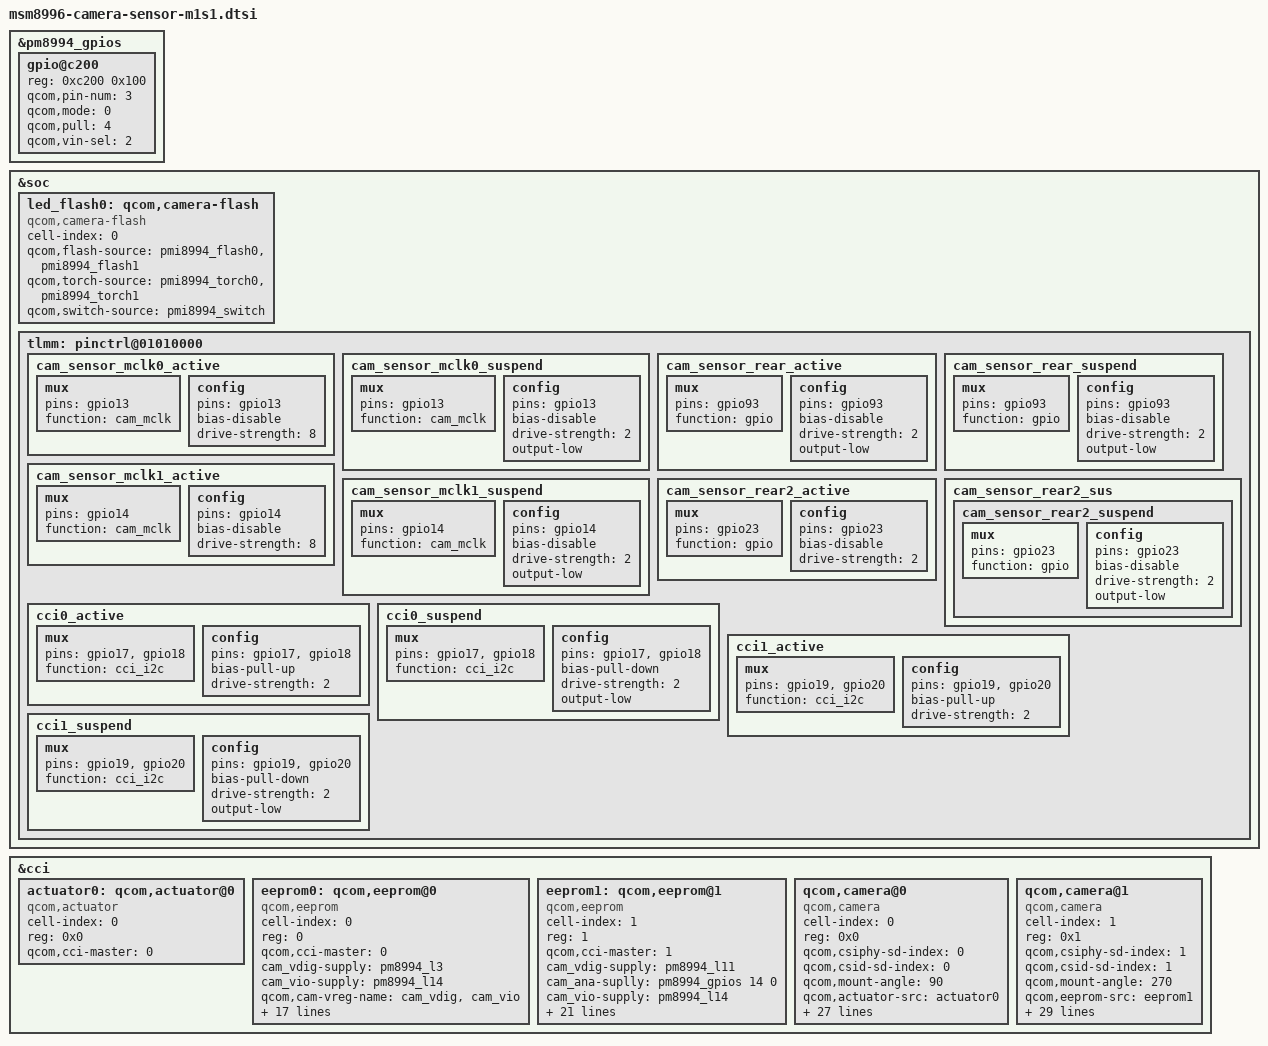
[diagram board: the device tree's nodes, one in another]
/*
 * Copyright (c) 2015, The Linux Foundation. All rights reserved.
 *
 * This program is free software; you can redistribute it and/or modify
 * it under the terms of the GNU General Public License version 2 and
 * only version 2 as published by the Free Software Foundation.
 *
 * This program is distributed in the hope that it will be useful,
 * but WITHOUT ANY WARRANTY; without even the implied warranty of
 * MERCHANTABILITY or FITNESS FOR A PARTICULAR PURPOSE.  See the
 * GNU General Public License for more details.
 */

&pm8994_gpios {
	gpio@c200 { /* Rear Camera VSYNC */
				reg = <0xc200 0x100>;
				qcom,pin-num = <3>;
				qcom,mode = <0>;     /* Digital Input */
				qcom,pull = <4>;     /* Pull Down*/
				qcom,vin-sel = <2>;  /* VIN2 */
				status = "ok";
			};
};

&soc {
	led_flash0: qcom,camera-flash {
		cell-index = <0>;
		compatible = "qcom,camera-flash";
		qcom,flash-source = <&pmi8994_flash0 &pmi8994_flash1>;
		qcom,torch-source = <&pmi8994_torch0 &pmi8994_torch1>;
		qcom,switch-source = <&pmi8994_switch>;
	};
	tlmm: pinctrl@01010000 {
	cam_sensor_mclk0_active: cam_sensor_mclk0_active {
		/* MCLK0 */
		mux {
			/* CLK, DATA */
			pins = "gpio13";
			function = "cam_mclk";
		};

		config {
			pins = "gpio13";
			bias-disable; /* No PULL */
			drive-strength = <8>; /*HTC modify 8 MA */
		};
	};
	cam_sensor_mclk0_suspend: cam_sensor_mclk0_suspend {
		/* MCLK0 */
		mux {
			/* CLK, DATA */
			pins = "gpio13";
			function = "cam_mclk";
		};

		config {
			pins = "gpio13";
			bias-disable; /*HTC modify No PULL */
			drive-strength = <2>; /*HTC modify 8 MA */
			output-low; /*HTC ADD*/
		};
	};
	cam_sensor_rear_active: cam_sensor_rear_active {
		/* RESET, STANDBY */
		mux {
			pins = "gpio93";/*HTC modify */
			function = "gpio";
		};

		config {
			pins = "gpio93";/*HTC modify */
			bias-disable; /* No PULL */
			drive-strength = <2>; /* 2 MA */
			output-low; /*HTC ADD*/
		};
	};
	cam_sensor_rear_suspend: cam_sensor_rear_suspend{
		/* RESET, STANDBY */
		mux {
			pins = "gpio93";/*HTC modify */
			function = "gpio";
		};

		config {
			pins = "gpio93";/*HTC modify */
			bias-disable; /* No PULL */
			drive-strength = <2>; /* 2 MA */
			output-low; /*HTC ADD*/
		};
	};
	cam_sensor_mclk1_active: cam_sensor_mclk1_active{
		/* MCLK1 */
		mux {
			/* CLK, DATA */
			pins = "gpio14";
			function = "cam_mclk";
		};

		config {
			pins = "gpio14";
			bias-disable; /* No PULL */
			drive-strength = <8>; /*HTC modify 8 MA */
		};
	};

	cam_sensor_mclk1_suspend: cam_sensor_mclk1_suspend {
		/* MCLK1 */
		mux {
			/* CLK, DATA */
			pins = "gpio14";
			function = "cam_mclk";
		};

		config {
			pins = "gpio14";
			bias-disable; /*HTC modify No PULL */
			drive-strength = <2>; /*HTC modify 8 MA */
			output-low; /*HTC ADD*/
		};
	};

	cam_sensor_rear2_active: cam_sensor_rear2_active {
		/* RESET, STANDBY */
		mux {
			pins = "gpio23"; /*HTC modify*/
			function = "gpio";
		};

		config {
			pins = "gpio23"; /*HTC modify*/
			bias-disable; /* No PULL */
			drive-strength = <2>; /* 2 MA */
		};
	};

	cam_sensor_rear2_sus {
		cam_sensor_rear2_suspend: cam_sensor_rear2_suspend{
			/* RESET, STANDBY */
			mux {
				pins = "gpio23"; /*HTC modify*/
				function = "gpio";
			};

			config {
				pins = "gpio23"; /*HTC modify*/
				bias-disable; /* No PULL */
				drive-strength = <2>; /* 2 MA */
				output-low; /*HTC ADD*/
			};
		};
	};
		cci0_active: cci0_active {
			mux {
				/* CLK, DATA */
				pins = "gpio17","gpio18"; // Only 2
				function = "cci_i2c";
			};

			config {
				pins = "gpio17","gpio18";
				bias-pull-up; /* PULL UP*/
				drive-strength = <2>; /* 2 MA */
			};
		};

		cci0_suspend: cci0_suspend {
			mux {
				/* CLK, DATA */
				pins = "gpio17","gpio18";
				function = "cci_i2c";
			};

			config {
				pins = "gpio17","gpio18";
				bias-pull-down; /* PULL DOWN */
				drive-strength = <2>; /* 2 MA */
				output-low; /*HTC ADD*/
			};
		};

		cci1_active: cci1_active {
			mux {
				/* CLK, DATA */
				pins = "gpio19","gpio20";
				function = "cci_i2c";
			};

			config {
				pins = "gpio19","gpio20";
				bias-pull-up; /* PULL UP*/
				drive-strength = <2>; /* 2 MA */
			};
		};

		cci1_suspend: cci1_suspend {
			mux {
				/* CLK, DATA */
				pins = "gpio19","gpio20";
				function = "cci_i2c";
			};

			config {
				pins = "gpio19","gpio20";
				bias-pull-down; /* PULL DOWN */
				drive-strength = <2>; /* 2 MA */
				output-low; /*HTC ADD*/
			};
		};
    };
};
&cci {
actuator0: qcom,actuator@0 {
        cell-index = <0>;
        reg = <0x0>;
        compatible = "qcom,actuator";
        qcom,cci-master = <0>;
};
eeprom0: qcom,eeprom@0 {
		cell-index = <0>;
		reg = <0>;
		compatible = "qcom,eeprom";
		qcom,cci-master = <0>;
		cam_vdig-supply = <&pm8994_l3>;
		cam_vio-supply = <&pm8994_l14>;
		qcom,cam-vreg-name = "cam_vdig", "cam_vio";
		qcom,cam-vreg-min-voltage = <1100000 1800000>;
		qcom,cam-vreg-max-voltage = <1100000 1800000>;
		qcom,cam-vreg-op-mode = <0 0>;
		qcom,gpio-no-mux = <0>;
		pinctrl-names = "cam_default", "cam_suspend";
		pinctrl-0 = <&cam_sensor_mclk0_active &cam_sensor_rear_active>;
		pinctrl-1 = <&cam_sensor_mclk0_suspend
				&cam_sensor_rear_suspend>;
		gpios = <&tlmm 13 0>,
			<&tlmm 93 0>,
			<&tlmm 49 0>;
		qcom,gpio-reset = <1>;
		qcom,gpio-vana = <2>;
		qcom,gpio-req-tbl-num = <0 1 2>;
		qcom,gpio-req-tbl-flags = <1 0 0>;
	    qcom,gpio-req-tbl-label = "CAMIF_MCLK",
					"CAM_RST",
					"CAM1_A2V8";
	    clocks = <&clock_mmss clk_mclk0_clk_src>,
				<&clock_mmss clk_camss_mclk0_clk>;
		clock-names = "cam_src_clk", "cam_clk";
};
eeprom1: qcom,eeprom@1 {
        cell-index = <1>;
        reg = <1>;
        compatible = "qcom,eeprom";
        qcom,cci-master = <1>;
        cam_vdig-supply = <&pm8994_l11>;
        cam_ana-suplly = <&pm8994_gpios 14 0>;
        cam_vio-supply = <&pm8994_l14>;
        qcom,cam-vreg-name = "cam_vdig", "cam_vio", "cam_vana";
        qcom,cam-vreg-min-voltage = <1200000 1800000 2850000>;
        qcom,cam-vreg-max-voltage = <1200000 1800000 2850000>;
        qcom,cam-vreg-op-mode = <0 0 0>;//uA
        qcom,gpio-no-mux = <0>;
        pinctrl-names = "cam_default", "cam_suspend";
        pinctrl-0 = <&cam_sensor_mclk1_active &cam_sensor_rear2_active>;
        pinctrl-1 = <&cam_sensor_mclk1_suspend &cam_sensor_rear2_suspend>;
        gpios = <&tlmm 14 0>,
            <&tlmm 23 0>,
            <&pm8994_gpios 14 0>;
        qcom,gpio-reset = <1>;
        qcom,gpio-vana = <2>;
        qcom,gpio-req-tbl-num = <0 1 2>;
        qcom,gpio-req-tbl-flags = <1 0 0>;
        qcom,gpio-req-tbl-label = "CAMIF_MCLK1",
                    "CAM_RST1",
                    "CAM2_A2V8";
        clocks = <&clock_mmss clk_mclk1_clk_src>,
                <&clock_mmss clk_camss_mclk1_clk>;
        clock-names = "cam_src_clk", "cam_clk";
};
qcom,camera@0 {
		cell-index = <0>;
		compatible = "qcom,camera";
		reg = <0x0>;
		qcom,csiphy-sd-index = <0>;
		qcom,csid-sd-index = <0>;
		qcom,mount-angle = <90>;
		qcom,actuator-src = <&actuator0>;
		qcom,led-flash-src = <&led_flash0>;
		qcom,eeprom-src = <&eeprom0>;
		qcom,camera-ver = <2>;
		cam_vdig-supply = <&pm8994_l3>;//212mA
		cam_vio-supply = <&pm8994_l14>;//7mA
		qcom,cam-vreg-name = "cam_vdig", "cam_vio";
		qcom,cam-vreg-type = <0 0>;
		qcom,cam-vreg-min-voltage = <1100000 1800000>;
		qcom,cam-vreg-max-voltage = <1100000 1800000>;
		qcom,cam-vreg-op-mode = <0 0>;//uA
		qcom,gpio-no-mux = <0>;
		pinctrl-names = "cam_default", "cam_suspend";
		pinctrl-0 = <&cam_sensor_mclk0_active &cam_sensor_rear_active>;
		pinctrl-1 = <&cam_sensor_mclk0_suspend &cam_sensor_rear_suspend>;
		gpios = <&tlmm 13 0>,
			<&tlmm 93 0>,
			<&tlmm 49 0>;
		qcom,gpio-reset = <1>;
		qcom,gpio-vana = <2>;
		qcom,gpio-req-tbl-num = <0 1 2>;
		qcom,gpio-req-tbl-flags = <1 0 0>;
		qcom,gpio-req-tbl-label = "CAMIF_MCLK",
					"CAM_RST",
					"CAM1_A2V8";
		qcom,sensor-position = <0>;
		qcom,sensor-mode = <0>;
		qcom,cci-master = <0>;
		status = "ok";
		clocks = <&clock_mmss clk_mclk0_clk_src>,
				<&clock_mmss clk_camss_mclk0_clk>;
		clock-names = "cam_src_clk", "cam_clk";
	};

qcom,camera@1 {
		cell-index = <1>;
		compatible = "qcom,camera";
		reg = <0x1>;
		qcom,csiphy-sd-index = <1>;
		qcom,csid-sd-index = <1>;
		qcom,mount-angle = <270>;
		//qcom,led-flash-src = <&led_flash1>;
		//qcom,actuator-src = <&actuator1>;
		qcom,eeprom-src = <&eeprom1>;
		qcom,camera-ver = <2>;
		cam_vdig-supply = <&pm8994_l11>;//212mA
		cam_ana-suplly = <&pm8994_gpios 14 0>;
		cam_vio-supply = <&pm8994_l14>;//7mA
		qcom,cam-vreg-name = "cam_vdig", "cam_vio", "cam_vana";
		qcom,cam-vreg-type = <0 2 0>;
		qcom,cam-vreg-min-voltage = <1200000 1800000 2850000>;
		qcom,cam-vreg-max-voltage = <1200000 1800000 2850000>;
		qcom,cam-vreg-op-mode = <0 0 0>;//uA
		qcom,gpio-no-mux = <0>;
		pinctrl-names = "cam_default", "cam_suspend";
		pinctrl-0 = <&cam_sensor_mclk1_active &cam_sensor_rear2_active>;
		pinctrl-1 = <&cam_sensor_mclk1_suspend &cam_sensor_rear2_suspend>;
		gpios = <&tlmm 14 0>,
			<&tlmm 23 0>,
			<&pm8994_gpios 14 0>;
		qcom,gpio-reset = <1>;
		qcom,gpio-vana = <2>;
		qcom,gpio-req-tbl-num = <0 1 2>;
		qcom,gpio-req-tbl-flags = <1 0 0>;
		qcom,gpio-req-tbl-label = "CAMIF_MCLK1",
					"CAM_RST1",
					"CAM2_A2V8";
		qcom,sensor-position = <1>;
		qcom,sensor-mode = <1>;
		qcom,cci-master = <1>;
		status = "ok";
		clocks = <&clock_mmss clk_mclk1_clk_src>,
				<&clock_mmss clk_camss_mclk1_clk>;
		clock-names = "cam_src_clk", "cam_clk";
	};
};
